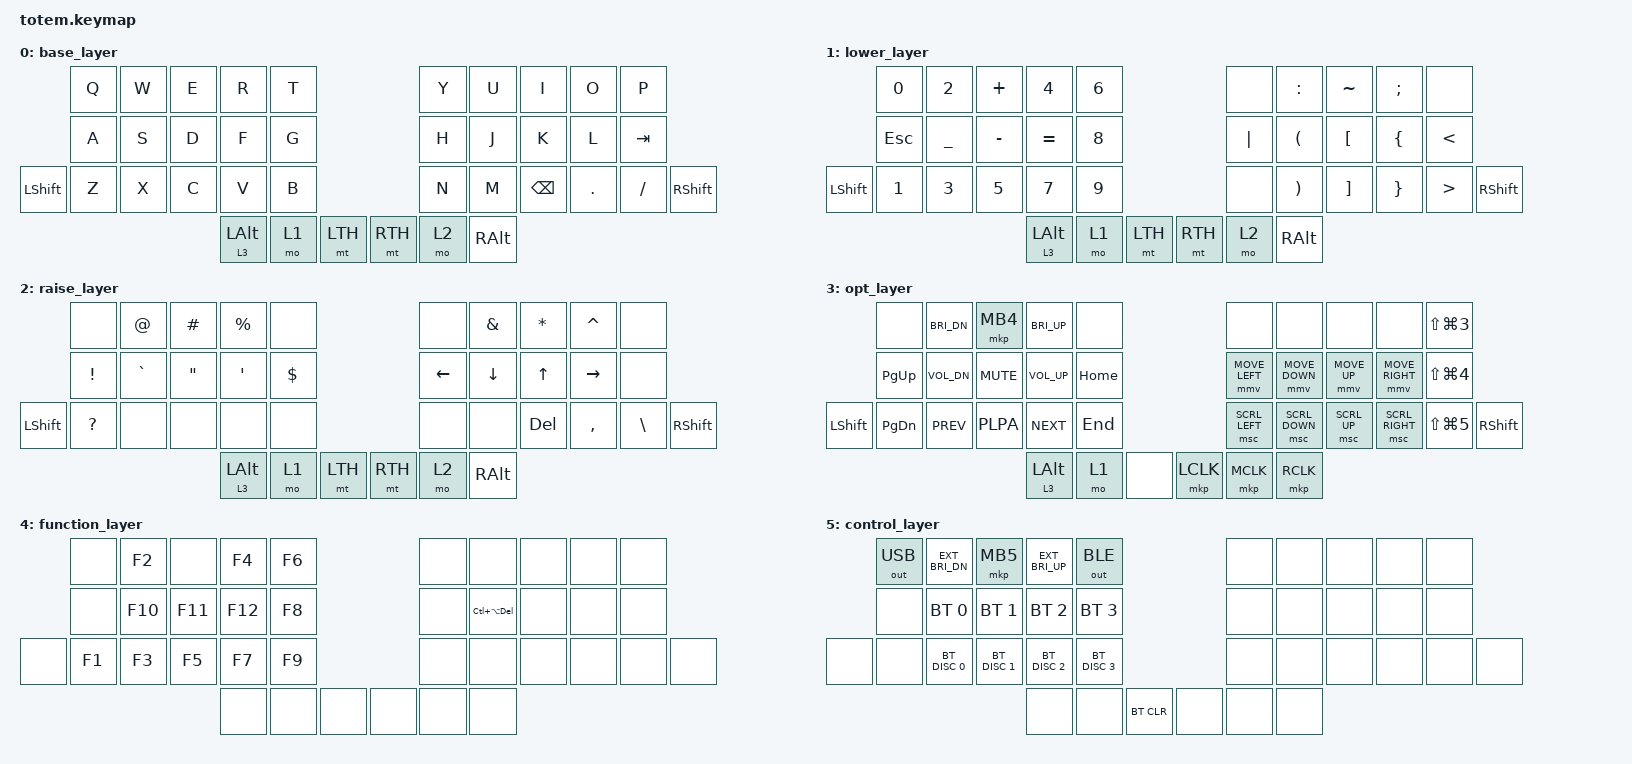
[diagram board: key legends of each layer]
#include <behaviors.dtsi>

#include <dt-bindings/zmk/bt.h>
#include <dt-bindings/zmk/keys.h>
#include <dt-bindings/zmk/pointing.h>
#include <dt-bindings/zmk/outputs.h>
#include <dt-bindings/zmk/behaviors.h>

#define LTH LCTRL SPACE
#define RTH LMETA RET

#define VOL_UP C_VOL_UP
#define VOL_DN C_VOL_DN
#define MUTE   C_MUTE

#define BRI_UP C_BRI_UP
#define EXT_BRI_UP LC(BRI_UP)
#define BRI_DN C_BRI_DN
#define EXT_BRI_DN LC(BRI_DN)

#define PLPA   C_PLAY_PAUSE
#define NEXT   C_NEXT
#define PREV   C_PREV

#define LTSHFT &kp LSHIFT
#define RTSHFT &kp RSHIFT

#define ZMK_POINTING_DEFAULT_MOVE_VAL 900
#define ZMK_POINTING_DEFAULT_SCRL_VAL 20

&sk {
  release-after-ms = <3000>;
  quick-release;
};

&mt {
  tapping-term-ms = <160>;
  quick-tap-ms = <200>;
};

/ {
  combos {
    compatible = "zmk,combos";
    
    combo_momentary_layer {
      timeout-ms = <100>;
      key-positions = <32 20>; // if Opt and Left Shift are pressed
      bindings = <&mo 5>;
    };
  };
};

/ {
  behaviors {
    lts: layer_tap_sticky {
      compatible = "zmk,behavior-hold-tap";
      #binding-cells = <2>;
      flavor = "tap-preferred";
      tapping-term-ms = <160>;
      bindings = <&mo>, <&sk>;
      display-name = "Layer-Tap-Sticky";
    };
  };

  conditional_layers {
    compatible = "zmk,conditional-layers";

    function_layer {
      if-layers = <1 2>;
      then-layer = <4>;
    };
  };

  keymap {
    compatible = "zmk,keymap";

    base_layer {
      bindings = <
                 &kp Q  &kp W  &kp E  &kp R       &kp T                   &kp Y   &kp U  &kp I    &kp O    &kp P
                 &kp A  &kp S  &kp D  &kp F       &kp G                   &kp H   &kp J  &kp K    &kp L    &kp TAB
        LTSHFT   &kp Z  &kp X  &kp C  &kp V       &kp B                   &kp N   &kp M  &kp BSPC &kp DOT  &kp FSLH  RTSHFT
                                      &lts 3 LALT &mo 1 &mt LTH   &mt RTH &mo 2   &kp RALT
      >;
    };

    lower_layer {
      bindings = <
                &kp N0  &kp N2    &kp PLUS  &kp N4      &kp N6                   &none    &kp COLON  &kp TILDE  &kp SEMI  &none
                &kp ESC &kp UNDER &kp MINUS &kp EQUAL   &kp N8                   &kp PIPE &kp LPAR   &kp LBKT   &kp LBRC  &kp LT
        LTSHFT  &kp N1  &kp N3    &kp N5    &kp N7      &kp N9                   &none    &kp RPAR   &kp RBKT   &kp RBRC  &kp GT  RTSHFT
                                            &lts 3 LALT &mo 1  &mt LTH   &mt RTH &mo 2    &kp RALT
      >;
    };

    raise_layer {
      bindings = <
               &none     &kp AT    &kp HASH &kp PRCNT    &none                     &none        &kp AMPS   &kp ASTRK &kp CARET  &none
               &kp EXCL  &kp GRAVE &kp DQT  &kp SQT      &kp DLLR                  &kp LEFT     &kp DOWN   &kp UP    &kp RIGHT  &none
        LTSHFT &kp QMARK &none     &none    &none        &none                     &none        &none      &kp DEL   &kp COMMA  &kp BSLH  RTSHFT
                                            &lts 3 LALT  &mo 1  &mt LTH   &mt RTH  &mo 2        &kp RALT
      >;
    };

    opt_layer {
      bindings = <
                &none        &kp BRI_DN  &mkp MB4     &kp BRI_UP  &none                               &none          &none           &none        &none            &kp LS(LG(N3))
                &kp PG_UP    &kp VOL_DN  &kp MUTE     &kp VOL_UP  &kp HOME                            &mmv MOVE_LEFT &mmv MOVE_DOWN  &mmv MOVE_UP &mmv MOVE_RIGHT  &kp LS(LG(N4))
        LTSHFT  &kp PG_DN    &kp PREV    &kp PLPA     &kp NEXT    &kp END                             &msc SCRL_LEFT &msc SCRL_DOWN  &msc SCRL_UP &msc SCRL_RIGHT  &kp LS(LG(N5))  RTSHFT
                                                      &lts 3 LALT &mo 1   &none            &mkp LCLK  &mkp MCLK      &mkp RCLK
      >;
    };

    function_layer {
      bindings = <
               &none   &kp F2   &none   &kp F4    &kp F6                     &none  &none            &none  &none  &none
               &none   &kp F10  &kp F11 &kp F12   &kp F8                     &none  &kp LC(LA(DEL))  &none  &none  &none
        &none  &kp F1  &kp F3   &kp F5  &kp F7    &kp F9                     &none  &none            &none  &none  &none  &none
                                        &none     &none  &none        &none  &none  &none
      >;
    };

    control_layer {
      bindings = <
               &out OUT_USB  &kp EXT_BRI_DN &mkp MB5      &kp EXT_BRI_UP &out OUT_BLE               &none  &none  &none  &none  &none
               &none         &bt BT_SEL 0   &bt BT_SEL 1  &bt BT_SEL 2   &bt BT_SEL 3               &none  &none  &none  &none  &none
        &none  &none         &bt BT_DISC 0  &bt BT_DISC 1 &bt BT_DISC 2  &bt BT_DISC 3              &none  &none  &none  &none  &none  &none
                                                          &none          &none  &bt BT_CLR          &none  &none  &none
      >;
    };
  };
};
